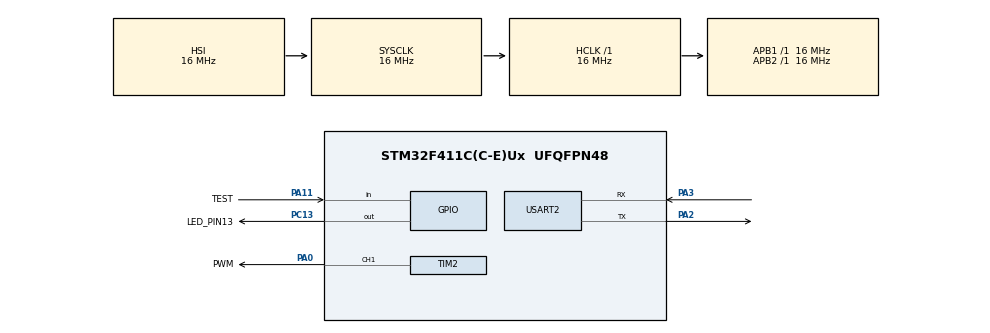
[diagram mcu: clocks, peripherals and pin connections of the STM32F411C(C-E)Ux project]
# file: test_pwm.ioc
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Mcu.Family=STM32F4
Mcu.Name=STM32F411C(C-E)Ux
Mcu.Package=UFQFPN48
NVIC.PriorityGroup=NVIC_PRIORITYGROUP_4
PA0-WKUP.GPIO_Label=PWM
PA0-WKUP.Signal=S_TIM2_CH1_ETR
PA11.GPIO_Label=TEST
PA11.Signal=GPIO_Input
PA2.Mode=Asynchronous
PA2.Signal=USART2_TX
PA3.Mode=Asynchronous
PA3.Signal=USART2_RX
PC13-ANTI_TAMP.GPIO_Label=LED_PIN13
PC13-ANTI_TAMP.Signal=GPIO_Output
ProjectManager.HeapSize=0x200
ProjectManager.StackSize=0x400
ProjectManager.TargetToolchain=STM32CubeIDE
RCC.AHBFreq_Value=16000000
RCC.APB1Freq_Value=16000000
RCC.APB2Freq_Value=16000000
RCC.CortexFreq_Value=16000000
RCC.HSE_VALUE=25000000
RCC.HSI_VALUE=16000000
RCC.LSE_VALUE=32768
RCC.SYSCLKFreq_VALUE=16000000
RCC.VCOOutputFreq_Value=192000000
SH.S_TIM2_CH1_ETR.0=TIM2_CH1,PWM Generation1 CH1
TIM2.AutoReloadPreload=TIM_AUTORELOAD_PRELOAD_ENABLE
TIM2.Channel-PWM\ Generation1\ CH1=TIM_CHANNEL_1
TIM2.Period=1400
TIM2.Prescaler=65535
TIM2.Pulse-PWM\ Generation1\ CH1=700
USART2.VirtualMode=VM_ASYNC
VP_TIM2_VS_ClockSourceINT.Mode=Internal
board=custom

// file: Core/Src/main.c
/* USER CODE BEGIN Header */
/**
  ******************************************************************************
  * @file           : main.c
  * @brief          : Main program body
  ******************************************************************************
  * @attention
  *
  * Copyright (c) 2022 STMicroelectronics.
  * All rights reserved.
  *
  * This software is licensed under terms that can be found in the LICENSE file
  * in the root directory of this software component.
  * If no LICENSE file comes with this software, it is provided AS-IS.
  *
  ******************************************************************************
  */
/* USER CODE END Header */
#include "main.h"

/* USER CODE BEGIN Includes */
#include <stdio.h>
#include "retarget.h"
/* USER CODE END Includes */

TIM_HandleTypeDef htim2;

UART_HandleTypeDef huart2;

void SystemClock_Config(void);
static void MX_GPIO_Init(void);
static void MX_TIM2_Init(void);
static void MX_USART2_UART_Init(void);

/* USER CODE BEGIN 0 */
int global_pulse_width = 100;
/* USER CODE END 0 */

int main(void)
{

  /* MCU Configuration--------------------------------------------------------*/

  /* Reset of all peripherals, Initializes the Flash interface and the Systick. */
  HAL_Init();

  /* Configure the system clock */
  SystemClock_Config();

  /* Initialize all configured peripherals */
  MX_GPIO_Init();
  MX_TIM2_Init();
  MX_USART2_UART_Init();
  /* USER CODE BEGIN 2 */
  RetargetInit(&huart2);
  HAL_TIM_PWM_Start(&htim2, TIM_CHANNEL_1);

  /* USER CODE END 2 */
  HAL_Delay(10000);
  __HAL_TIM_SET_COMPARE(&htim2, TIM_CHANNEL_1, 500);

  /* Infinite loop */
  /* USER CODE BEGIN WHILE */

  while (1)
  {
	  /*state = HAL_GPIO_ReadPin(TEST_GPIO_Port, TEST_Pin);
      printf("state = %d\n", state);
	  if(state == 1)
		  HAL_GPIO_WritePin(LED_PIN13_GPIO_Port, LED_PIN13_Pin, GPIO_PIN_SET); //eteint la LED
	  else
		  HAL_GPIO_WritePin(LED_PIN13_GPIO_Port, LED_PIN13_Pin, GPIO_PIN_RESET); //allume la LED

	  HAL_Delay(100);
	  __HAL_TIM_SET_COMPARE(&htim2, TIM_CHANNEL_1, i = i+step);*/

  }
    /* USER CODE END WHILE */

}

void SystemClock_Config(void)
{
  RCC_OscInitTypeDef RCC_OscInitStruct = {0};
  RCC_ClkInitTypeDef RCC_ClkInitStruct = {0};

  /** Configure the main internal regulator output voltage
  */
  __HAL_RCC_PWR_CLK_ENABLE();
  __HAL_PWR_VOLTAGESCALING_CONFIG(PWR_REGULATOR_VOLTAGE_SCALE1);
  /** Initializes the RCC Oscillators according to the specified parameters
  * in the RCC_OscInitTypeDef structure.
  */
  RCC_OscInitStruct.OscillatorType = RCC_OSCILLATORTYPE_HSI;
  RCC_OscInitStruct.HSIState = RCC_HSI_ON;
  RCC_OscInitStruct.HSICalibrationValue = RCC_HSICALIBRATION_DEFAULT;
  RCC_OscInitStruct.PLL.PLLState = RCC_PLL_NONE;
  if (HAL_RCC_OscConfig(&RCC_OscInitStruct) != HAL_OK)
  {
    Error_Handler();
  }
  /** Initializes the CPU, AHB and APB buses clocks
  */
  RCC_ClkInitStruct.ClockType = RCC_CLOCKTYPE_HCLK|RCC_CLOCKTYPE_SYSCLK
                              |RCC_CLOCKTYPE_PCLK1|RCC_CLOCKTYPE_PCLK2;
  RCC_ClkInitStruct.SYSCLKSource = RCC_SYSCLKSOURCE_HSI;
  RCC_ClkInitStruct.AHBCLKDivider = RCC_SYSCLK_DIV1;
  RCC_ClkInitStruct.APB1CLKDivider = RCC_HCLK_DIV1;
  RCC_ClkInitStruct.APB2CLKDivider = RCC_HCLK_DIV1;

  if (HAL_RCC_ClockConfig(&RCC_ClkInitStruct, FLASH_LATENCY_0) != HAL_OK)
  {
    Error_Handler();
  }
}

static void MX_TIM2_Init(void)
{

  TIM_ClockConfigTypeDef sClockSourceConfig = {0};
  TIM_MasterConfigTypeDef sMasterConfig = {0};
  TIM_OC_InitTypeDef sConfigOC = {0};

  htim2.Instance = TIM2;
  htim2.Init.Prescaler = 0;
  htim2.Init.CounterMode = TIM_COUNTERMODE_UP;
  htim2.Init.Period = 5000;
  htim2.Init.ClockDivision = TIM_CLOCKDIVISION_DIV1;
  htim2.Init.AutoReloadPreload = TIM_AUTORELOAD_PRELOAD_ENABLE;
  if (HAL_TIM_Base_Init(&htim2) != HAL_OK)
  {
    Error_Handler();
  }
  sClockSourceConfig.ClockSource = TIM_CLOCKSOURCE_INTERNAL;
  if (HAL_TIM_ConfigClockSource(&htim2, &sClockSourceConfig) != HAL_OK)
  {
    Error_Handler();
  }
  if (HAL_TIM_PWM_Init(&htim2) != HAL_OK)
  {
    Error_Handler();
  }
  sMasterConfig.MasterOutputTrigger = TIM_TRGO_RESET;
  sMasterConfig.MasterSlaveMode = TIM_MASTERSLAVEMODE_DISABLE;
  if (HAL_TIMEx_MasterConfigSynchronization(&htim2, &sMasterConfig) != HAL_OK)
  {
    Error_Handler();
  }
  sConfigOC.OCMode = TIM_OCMODE_PWM1;
  sConfigOC.Pulse = 2500;
  sConfigOC.OCPolarity = TIM_OCPOLARITY_HIGH;
  sConfigOC.OCFastMode = TIM_OCFAST_DISABLE;
  if (HAL_TIM_PWM_ConfigChannel(&htim2, &sConfigOC, TIM_CHANNEL_1) != HAL_OK)
  {
    Error_Handler();
  }
  HAL_TIM_MspPostInit(&htim2);

}

static void MX_USART2_UART_Init(void)
{

  huart2.Instance = USART2;
  huart2.Init.BaudRate = 115200;
  huart2.Init.WordLength = UART_WORDLENGTH_8B;
  huart2.Init.StopBits = UART_STOPBITS_1;
  huart2.Init.Parity = UART_PARITY_NONE;
  huart2.Init.Mode = UART_MODE_TX_RX;
  huart2.Init.HwFlowCtl = UART_HWCONTROL_NONE;
  huart2.Init.OverSampling = UART_OVERSAMPLING_16;
  if (HAL_UART_Init(&huart2) != HAL_OK)
  {
    Error_Handler();
  }

}

static void MX_GPIO_Init(void)
{
  GPIO_InitTypeDef GPIO_InitStruct = {0};

  /* GPIO Ports Clock Enable */
  __HAL_RCC_GPIOC_CLK_ENABLE();
  __HAL_RCC_GPIOA_CLK_ENABLE();

  /*Configure GPIO pin Output Level */
  HAL_GPIO_WritePin(LED_PIN13_GPIO_Port, LED_PIN13_Pin, GPIO_PIN_RESET);

  /*Configure GPIO pin : LED_PIN13_Pin */
  GPIO_InitStruct.Pin = LED_PIN13_Pin;
  GPIO_InitStruct.Mode = GPIO_MODE_OUTPUT_PP;
  GPIO_InitStruct.Pull = GPIO_NOPULL;
  GPIO_InitStruct.Speed = GPIO_SPEED_FREQ_LOW;
  HAL_GPIO_Init(LED_PIN13_GPIO_Port, &GPIO_InitStruct);

  /*Configure GPIO pin : TEST_Pin */
  GPIO_InitStruct.Pin = TEST_Pin;
  GPIO_InitStruct.Mode = GPIO_MODE_INPUT;
  GPIO_InitStruct.Pull = GPIO_NOPULL;
  HAL_GPIO_Init(TEST_GPIO_Port, &GPIO_InitStruct);

}

void Error_Handler(void)
{
  __disable_irq();
  while (1)
  {
  }
}
